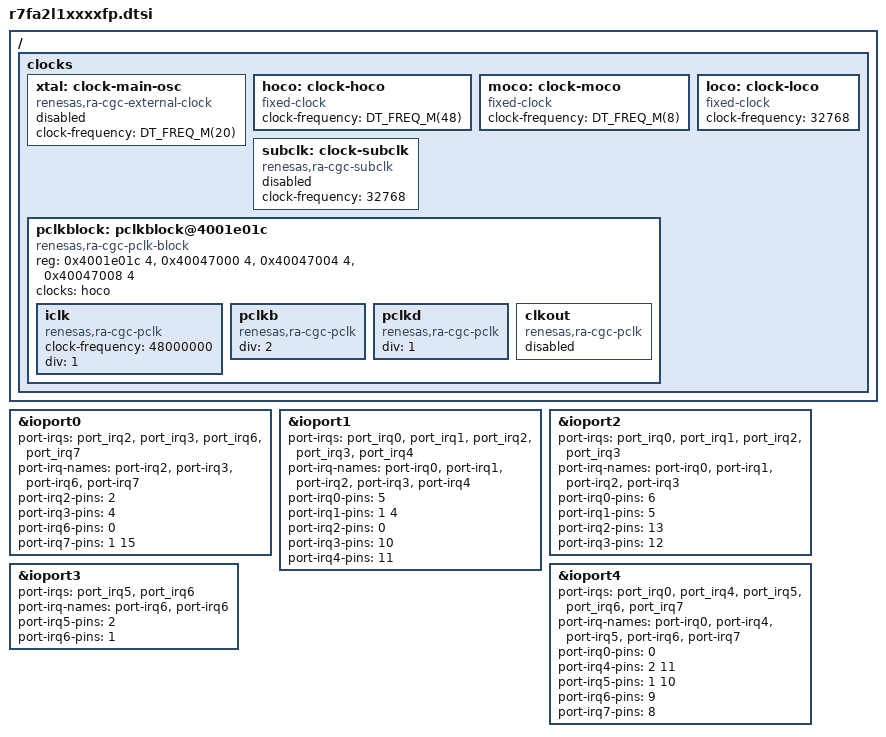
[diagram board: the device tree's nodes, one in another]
/**
 * Copyright (c) 2024 MUNIC SA
 * Copyright (c) 2024-2025 Renesas Electronics Corporation
 *
 * Renesas R7FA2AL1AxxxFP MCU device tree for 100 pins socket
 *
 * SPDX-License-Identifier: Apache-2.0
 *
 */

/ {
	clocks: clocks {
		#address-cells = <1>;
		#size-cells = <1>;

		xtal: clock-main-osc {
			compatible = "renesas,ra-cgc-external-clock";
			clock-frequency = <DT_FREQ_M(20)>;
			#clock-cells = <0>;
			status = "disabled";
		};

		hoco: clock-hoco {
			compatible = "fixed-clock";
			clock-frequency = <DT_FREQ_M(48)>;
			#clock-cells = <0>;
		};

		moco: clock-moco {
			compatible = "fixed-clock";
			clock-frequency = <DT_FREQ_M(8)>;
			#clock-cells = <0>;
		};

		loco: clock-loco {
			compatible = "fixed-clock";
			clock-frequency = <32768>;
			#clock-cells = <0>;
		};

		subclk: clock-subclk {
			compatible = "renesas,ra-cgc-subclk";
			clock-frequency = <32768>;
			#clock-cells = <0>;
			status = "disabled";
		};

		pclkblock: pclkblock@4001e01c {
			compatible = "renesas,ra-cgc-pclk-block";
			reg = <0x4001e01c 4>, <0x40047000 4>, <0x40047004 4>,
			      <0x40047008 4>;
			reg-names = "MSTPA", "MSTPB","MSTPC",
				    "MSTPD";
			#clock-cells = <0>;
			clocks = <&hoco>;
			status = "okay";

			iclk: iclk {
				compatible = "renesas,ra-cgc-pclk";
				clock-frequency = <48000000>;
				div = <1>;
				#clock-cells = <2>;
				status = "okay";
			};

			pclkb: pclkb {
				compatible = "renesas,ra-cgc-pclk";
				div = <2>;
				#clock-cells = <2>;
				status = "okay";
			};

			pclkd: pclkd {
				compatible = "renesas,ra-cgc-pclk";
				div = <1>;
				#clock-cells = <2>;
				status = "okay";
			};

			clkout: clkout {
				compatible = "renesas,ra-cgc-pclk";
				#clock-cells = <2>;
				status = "disabled";
			};

		};
	};
};

&ioport0 {
	port-irqs = <&port_irq2 &port_irq3 &port_irq6
	&port_irq7>;
	port-irq-names = "port-irq2",
			 "port-irq3",
			 "port-irq6",
			 "port-irq7";
	port-irq2-pins = <2>;
	port-irq3-pins = <4>;
	port-irq6-pins = <0>;
	port-irq7-pins = <1 15>;
};

&ioport1 {
	port-irqs = <&port_irq0 &port_irq1 &port_irq2
	&port_irq3 &port_irq4>;
	port-irq-names = "port-irq0",
			 "port-irq1",
			 "port-irq2",
			 "port-irq3",
			 "port-irq4";
	port-irq0-pins = <5>;
	port-irq1-pins = <1 4>;
	port-irq2-pins = <0>;
	port-irq3-pins = <10>;
	port-irq4-pins = <11>;
};

&ioport2 {
	port-irqs = <&port_irq0 &port_irq1 &port_irq2
	&port_irq3>;
	port-irq-names = "port-irq0",
			 "port-irq1",
			 "port-irq2",
			 "port-irq3";
	port-irq0-pins = <6>;
	port-irq1-pins = <5>;
	port-irq2-pins = <13>;
	port-irq3-pins = <12>;
};

&ioport3 {
	port-irqs = <&port_irq5 &port_irq6>;
	port-irq-names = "port-irq6",
			 "port-irq6";
	port-irq5-pins = <2>;
	port-irq6-pins = <1>;
};

&ioport4 {
	port-irqs = <&port_irq0 &port_irq4 &port_irq5
	&port_irq6 &port_irq7>;
	port-irq-names = "port-irq0",
			 "port-irq4",
			 "port-irq5",
			 "port-irq6",
			 "port-irq7";
	port-irq0-pins = <0>;
	port-irq4-pins = <2 11>;
	port-irq5-pins = <1 10>;
	port-irq6-pins = <9>;
	port-irq7-pins = <8>;
};
